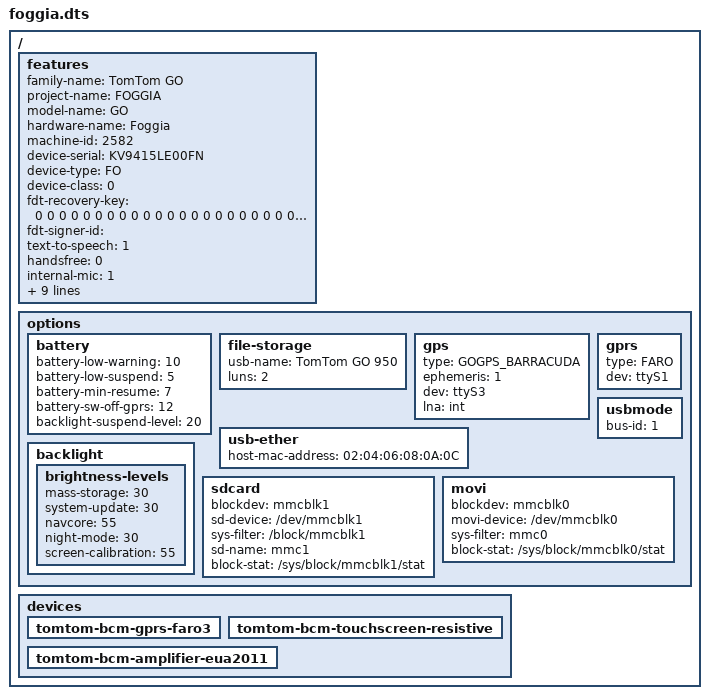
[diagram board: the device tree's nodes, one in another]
/dts-v1/;

/ {
	features 
	{
		family-name				= "TomTom GO";
		project-name				= "FOGGIA";
		model-name				= "GO";
		hardware-name				= "Foggia";
		machine-id				= <2582>;
		device-serial				= "KV9415LE00FN";
		device-type				= "FO";
		device-class				= <0>;
		fdt-recovery-key			= <
			0 0 0 0 0 0 0 0 0 0 0 0 0 0 0 0 0 0 0 0 0 0 0 0 0 0 0 0 0 0 0 0
			0 0 0 0 0 0 0 0 0 0 0 0 0 0 0 0 0 0 0 0 0 0 0 0 0 0 0 0 0 0 0 0
			0 0 0 0 0 0 0 0 0 0 0 0 0 0 0 0 0 0 0 0 0 0 0 0 0 0 0 0 0 0 0 0
			0 0 0 0 0 0 0 0 0 0 0 0 0 0 0 0 0 0 0 0 0 0 0 0 0 0 0 0 0 0 0 0
		>;
		fdt-signer-id				= "";
		text-to-speech				= <1>;
		handsfree				= <0>;
		internal-mic				= <1>;
		voice-recording				= <1>;
		connect-ext-mic				= <0>;
		sdcard					= <1>;
		uart-id					= <2>;
		has-gprs				= <1>;
		has-bluetooth				= <0>;
		bluetooth				= "";
		amplifier				= "EUA2011";
		tft 					= "LMS430";
	};

	options 
	{
		battery 
		{
			battery-low-warning		= <10>;
			battery-low-suspend		= <5>;
			battery-min-resume		= <7>;
			battery-sw-off-gprs		= <12>;
			backlight-suspend-level		= <20>;
		};

		file-storage 
		{
			usb-name			= "TomTom GO 950";
			luns				= <2>;
		};

		gps 
		{
			type 				= "GOGPS_BARRACUDA";
			ephemeris			= <1>;	
			dev				= "ttyS3";
			lna				= "int";
		};

		gprs 
		{
			type				= "FARO";
			dev				= "ttyS1";
		};

		usb-ether 
		{
			host-mac-address		= "02:04:06:08:0A:0C";
		};

		usbmode 
		{
			/* usbmode related , the id of the usbmode driver needs change */
			bus-id				= <1>; 
		};

		backlight 
		{
			brightness-levels 
			{
				mass-storage		= <30>;
				system-update		= <30>;
				navcore			= <55>;
				night-mode		= <30>;
				screen-calibration	= <55>;
			};
		};

		sdcard 
		{
			blockdev 			= "mmcblk1";
			sd-device 			= "/dev/mmcblk1";
			sys-filter		 	= "/block/mmcblk1";
			sd-name 			= "mmc1";
			block-stat		 	= "/sys/block/mmcblk1/stat";
		};

		movi 
		{ 
			blockdev 			= "mmcblk0";
			movi-device 			= "/dev/mmcblk0";
			sys-filter 			= "mmc0";
			block-stat 			= "/sys/block/mmcblk0/stat";
		};

	};

	/* list of tomtom methods that need implementing: adding items as devices
	will cause tt_setup to register the services */
	devices {
		tomtom-bcm-gprs-faro3 {};
		tomtom-bcm-touchscreen-resistive {};
		tomtom-bcm-amplifier-eua2011 {};
	};
};
